# STM32H503xx register map
File version: 1.0
Registers are 32-bit, read-write, reset 0x0 unless marked. A register's access mark holds for its fields unless they carry their own. Offsets are from the block's base; [hi:lo] are bit positions; {n}, {i} and the like mark numbered series.

## TAMP — Tamper and backup registers
Base 0x44007C00
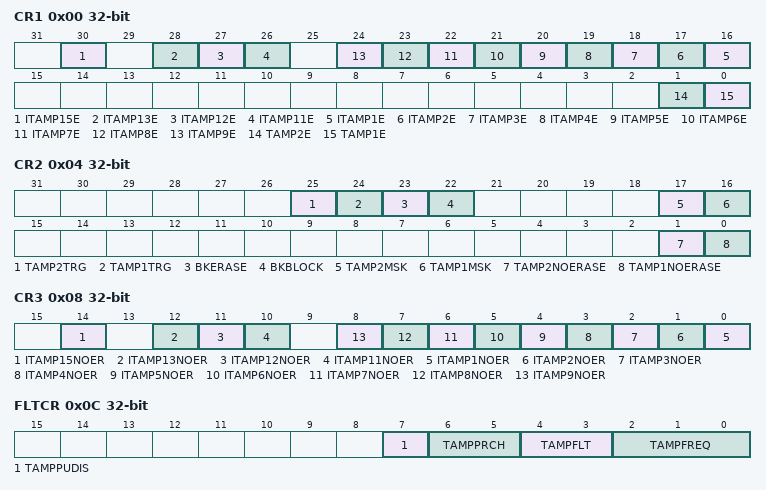
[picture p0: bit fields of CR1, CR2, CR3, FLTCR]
0x00 CR1 — TAMP control register 1
  [30] ITAMP15E, [28] ITAMP13E, [27] ITAMP12E, [26] ITAMP11E, [n+15] ITAMP{n}E (n=1..9), [1] TAMP2E, [0] TAMP1E
0x04 CR2 — TAMP control register 2
  [25] TAMP2TRG, [24] TAMP1TRG, [23] BKERASE, [22] BKBLOCK, [17] TAMP2MSK, [16] TAMP1MSK, [1] TAMP2NOERASE, [0] TAMP1NOERASE
0x08 CR3 — TAMP control register 3
  [14] ITAMP15NOER, [12] ITAMP13NOER, [11] ITAMP12NOER, [10] ITAMP11NOER, [n-1] ITAMP{n}NOER (n=1..9)
0x0C FLTCR — TAMP filter control register
  [7] TAMPPUDIS
  [6:5] TAMPPRCH
    0=DURATION_1RTCCLK (Tamper pins are pre-charged before sampling during 1 RTCCLK cycle); 1=DURATION_2RTCCLK (Tamper pins are pre-charged before sampling during 2 RTCCLK cycles); 2=DURATION_4RTCCLK (Tamper pins are pre-charged before sampling during 4 RTCCLK cycles); 3=DURATION_8RTCCLK (Tamper pins are pre-charged before sampling during 8 RTCCLK cycles)
  [4:3] TAMPFLT
    0=DISABLE (Tamper filter is disabled); 1=FILTER_2SAMPLE (Tamper is activated after 2 consecutive samples at the active level); 2=FILTER_4SAMPLE (Tamper is activated after 4 consecutive samples at the active level); 3=FILTER_8SAMPLE (Tamper is activated after 8 consecutive samples at the active level)
  [2:0] TAMPFREQ
    0=SAMPLFREQDIV_32768 (Each of the tamper inputs are sampled with a frequency = RTCCLK / 32768); 1=SAMPLFREQDIV_16384 (Each of the tamper inputs are sampled with a frequency = RTCCLK / 16384); 2=SAMPLFREQDIV_8192 (Each of the tamper inputs are sampled with a frequency = RTCCLK / 8192); 3=SAMPLFREQDIV_4096 (Each of the tamper inputs are sampled with a frequency = RTCCLK / 4096); 4=SAMPLFREQDIV_2048 (Each of the tamper inputs are sampled with a frequency = RTCCLK / 2048); 5=SAMPLFREQDIV_1024 (Each of the tamper inputs are sampled with a frequency = RTCCLK / 1024); 6=SAMPLFREQDIV_512 (Each of the tamper inputs are sampled with a frequency = RTCCLK / 512); 7=SAMPLFREQDIV_256 (Each of the tamper inputs are sampled with a frequency = RTCCLK / 256)
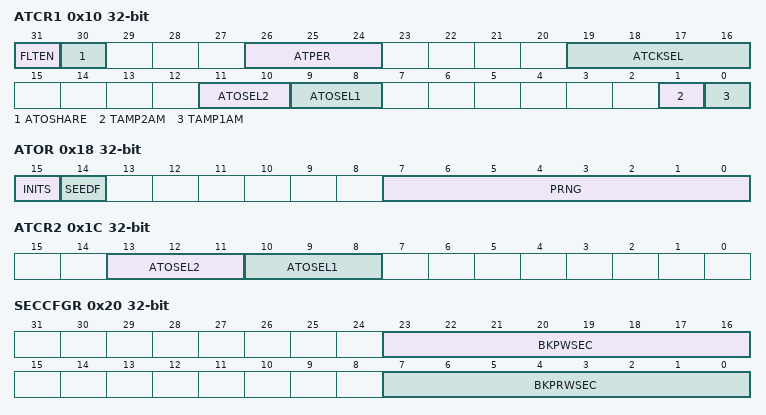
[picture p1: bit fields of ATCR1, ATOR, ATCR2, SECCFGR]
0x10 ATCR1 — TAMP filter control register 1
  [31] FLTEN, [30] ATOSHARE, [26:24] ATPER, [19:16] ATCKSEL, [11:10] ATOSEL2, [9:8] ATOSEL1, [1] TAMP2AM, [0] TAMP1AM
0x14 ATSEEDR — TAMP active tamper seed register
  [31:0] SEED
0x18 ATOR — TAMP active tamper output register
  [15] INITS, [14] SEEDF, [7:0] PRNG
0x1C ATCR2 — TAMP filter control register 2
  [13:11] ATOSEL2, [10:8] ATOSEL1
0x20 SECCFGR — TAMP secure mode control register
  [23:16] BKPWSEC, [7:0] BKPRWSEC
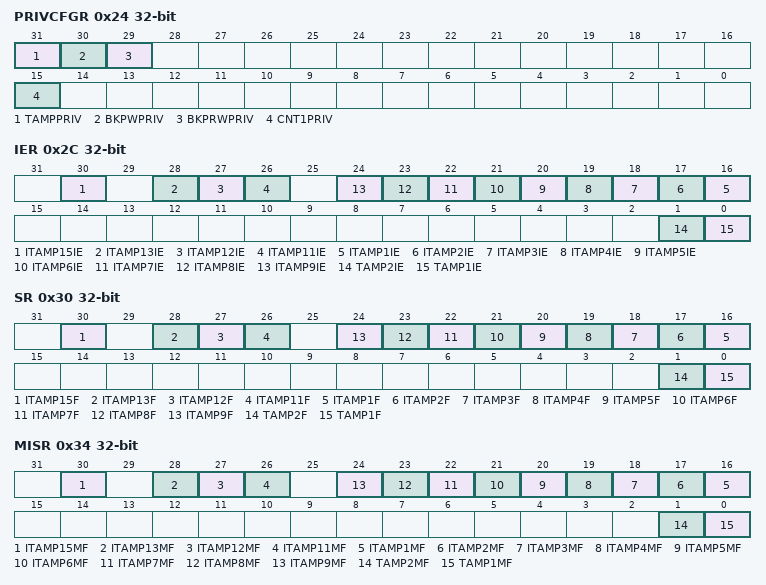
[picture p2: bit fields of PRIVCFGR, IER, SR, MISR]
0x24 PRIVCFGR — TAMP privilege mode control register
  [31] TAMPPRIV
    1=YES (TAMP full privilege); 0=NO (TAMP is not privilege)
  [30] BKPWPRIV
  [29] BKPRWPRIV
  [15] CNT1PRIV
0x2C IER — TAMP interrupt enable register
  [30] ITAMP15IE, [28] ITAMP13IE, [27] ITAMP12IE, [26] ITAMP11IE, [n+15] ITAMP{n}IE (n=1..9), [1] TAMP2IE, [0] TAMP1IE
0x30 SR — TAMP status register
  [30] ITAMP15F, [28] ITAMP13F, [27] ITAMP12F, [26] ITAMP11F, [n+15] ITAMP{n}F (n=1..9), [1] TAMP2F, [0] TAMP1F
0x34 MISR — TAMP masked interrupt status register
  [30] ITAMP15MF, [28] ITAMP13MF, [27] ITAMP12MF, [26] ITAMP11MF, [n+15] ITAMP{n}MF (n=1..9), [1] TAMP2MF, [0] TAMP1MF
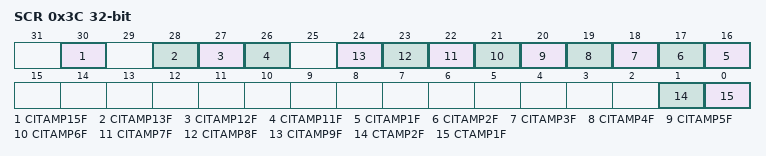
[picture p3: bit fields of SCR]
0x3C SCR — TAMP status clear register
  [30] CITAMP15F, [28] CITAMP13F, [27] CITAMP12F, [26] CITAMP11F, [n+15] CITAMP{n}F (n=1..9), [1] CTAMP2F, [0] CTAMP1F
0x40 COUNT1R — TAMP monotonic counter register
  [31:0] COUNT
0x50 OR — TAMP option register
0x54 ERCFGR — TAMP erase configuration register
  [0] ERCFG0
{0x100+4i} BKP{i}R (i=0..31) — TAMP backup register {i}

## PWR — Power Control
Base 0x44020800
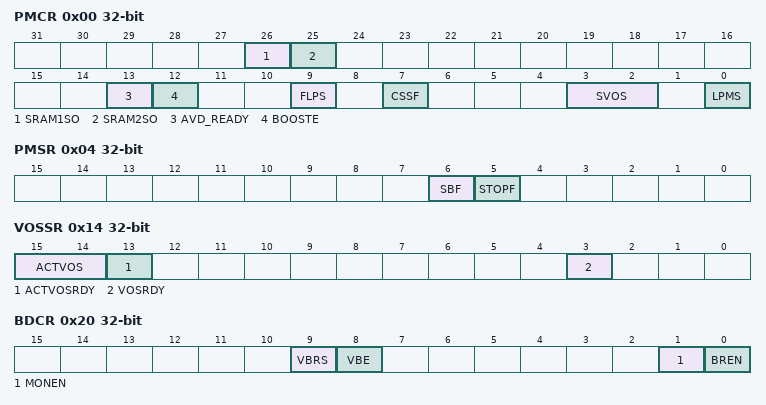
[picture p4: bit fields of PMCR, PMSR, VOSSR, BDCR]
0x00 PMCR — Power mode control register
  [26] SRAM1SO
  [25] SRAM2SO
  [13] AVD_READY
  [12] BOOSTE
  [9] FLPS
  [7] CSSF
  [3:2] SVOS
    3=SCALE3 (Select voltage scale 3 when system enters STOP mode); 2=SCALE4 (Select voltage scale 4 when system enters STOP mode); 1=SCALE5 (Select voltage scale 5 when system enters STOP mode)
  [0] LPMS
    0=STOP_MODE (STOP 0 mode); 1=STANDBY_MODE
0x04 PMSR — Power mode status register
  [6] SBF, [5] STOPF
0x10 VOSCR — Voltage scaling control register
  [5:4] VOS
    3=SCALE0 (Voltage scaling range 0); 2=SCALE1 (Voltage scaling range 1); 1=SCALE2 (Voltage scaling range 2); 0=SCALE3 (Voltage scaling range 3)
0x14 VOSSR — Voltage sacling status register
  [15:14] ACTVOS, [13] ACTVOSRDY, [3] VOSRDY
0x20 BDCR — BacKup domain control register
  [9] VBRS
    0=RESISTOR_5K (Charge the battery through a 5 kO resistor); 1=RESISTOR_1_5K (Charge the battery through a 1.5 kO resistor)
  [8] VBE
  [1] MONEN
  [0] BREN
0x24 DBPCR — DBP control register
  [0] DBP
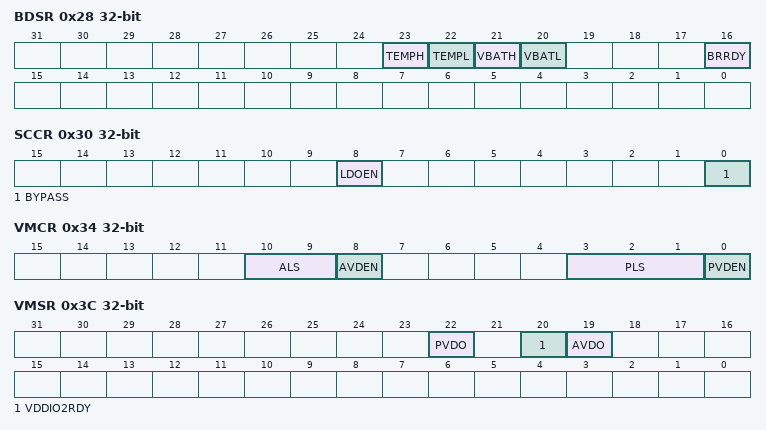
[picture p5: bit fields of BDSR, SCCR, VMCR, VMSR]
0x28 BDSR — BacKup domain status register
  [23] TEMPH, [22] TEMPL, [21] VBATH, [20] VBATL, [16] BRRDY
0x30 SCCR — Supply configuration control register
  [8] LDOEN, [0] BYPASS
0x34 VMCR — Voltage Monitor Control Register
  [10:9] ALS
    0=AVDLEVEL_0 (Analog Voltage threshold detected by AVD 1.7 V); 1=AVDLEVEL_1 (Analog Voltage threshold detected by AVD 2.1 V); 2=AVDLEVEL_2 (Analog Voltage threshold detected by AVD 2.5 V); 3=AVDLEVEL_3 (Analog Voltage threshold detected by AVD 2.8 V)
  [8] AVDEN
  [3:1] PLS
    0=PVDLEVEL_0 (Voltage threshold detected by PVD 1.95 V); 1=PVDLEVEL_1 (Voltage threshold detected by PVD 2.10 V); 2=PVDLEVEL_2 (Voltage threshold detected by PVD 2.25 V); 3=PVDLEVEL_3 (Voltage threshold detected by PVD 2.40 V); 4=PVDLEVEL_4 (Voltage threshold detected by PVD 2.55 V); 5=PVDLEVEL_5 (Voltage threshold detected by PVD 2.70 V); 6=PVDLEVEL_6 (Voltage threshold detected by PVD 2.85 V); 7=PVDLEVEL_7
  [0] PVDEN
0x3C VMSR — Status Register Voltage Monitoring
  [22] PVDO, [20] VDDIO2RDY, [19] AVDO
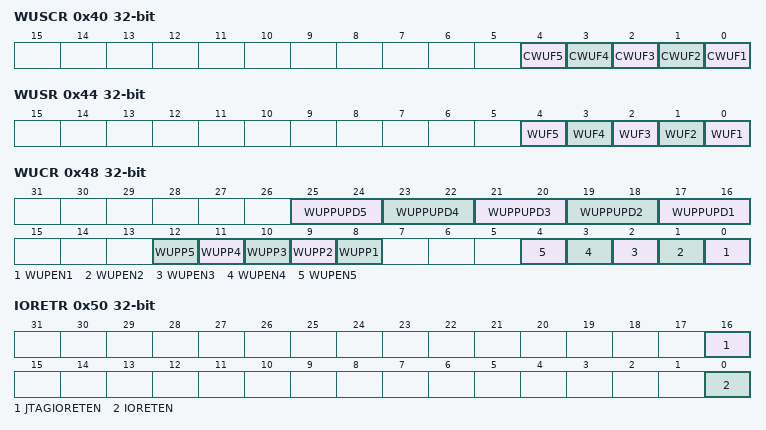
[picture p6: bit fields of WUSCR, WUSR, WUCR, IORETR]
0x40 WUSCR — WakeUP status clear register
  [n-1] CWUF{n} (n=1..5)
0x44 WUSR — WakeUP status Register
  [n-1] WUF{n} (n=1..5)
0x48 WUCR — WakeUP configuration register
  [2n+15:2n+14] WUPPUPD{n} (n=1..5), [n+7] WUPP{n} (n=1..5), [n-1] WUPEN{n} (n=1..5)
0x50 IORETR — IO RETention Register
  [16] JTAGIORETEN, [0] IORETEN
0x104 PRIVCFGR — Privilege configuration register
  [1] PRIV
